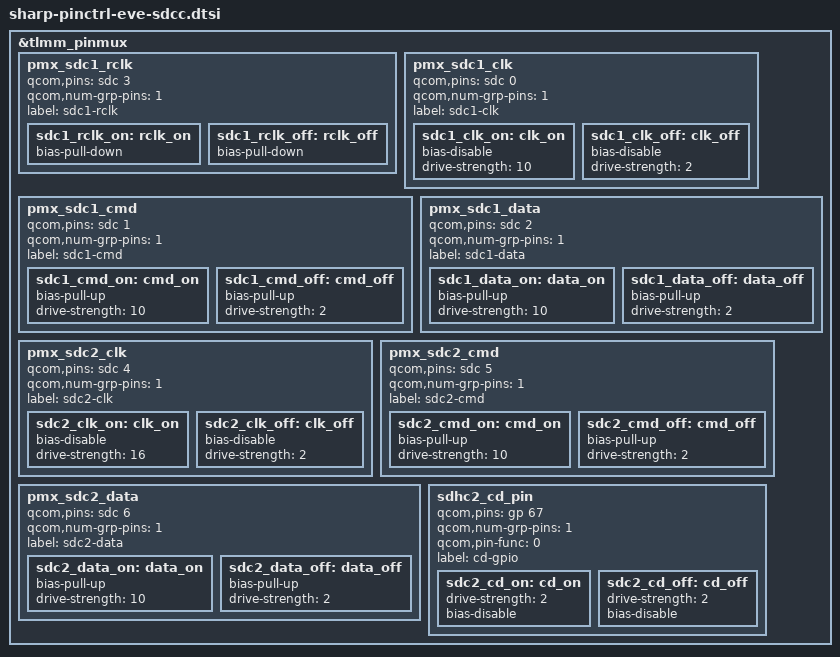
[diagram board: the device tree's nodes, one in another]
/* Copyright (c) 2015, The Linux Foundation. All rights reserved.
 *
 * This program is free software; you can redistribute it and/or modify
 * it under the terms of the GNU General Public License version 2 and
 * only version 2 as published by the Free Software Foundation.
 *
 * This program is distributed in the hope that it will be useful,
 * but WITHOUT ANY WARRANTY; without even the implied warranty of
 * MERCHANTABILITY or FITNESS FOR A PARTICULAR PURPOSE.  See the
 * GNU General Public License for more details.
 */

&tlmm_pinmux {
		pmx_sdc1_rclk {
			qcom,pins = <&sdc 3>;
			qcom,num-grp-pins = <1>;
			label = "sdc1-rclk";
			sdc1_rclk_on: rclk_on {
				bias-pull-down; /* pull down */
			};

			sdc1_rclk_off: rclk_off {
				bias-pull-down; /* pull down */
			};
		};

		pmx_sdc1_clk {
			qcom,pins = <&sdc 0>;
			qcom,num-grp-pins = <1>;
			label = "sdc1-clk";
			sdc1_clk_on: clk_on {
				bias-disable; /* NO pull */
				drive-strength = <10>; /* 10 MA */
			};
			sdc1_clk_off: clk_off {
				bias-disable; /* NO pull */
				drive-strength = <2>; /* 2 MA */
			};
		};

		pmx_sdc1_cmd {
			qcom,pins = <&sdc 1>;
			qcom,num-grp-pins = <1>;
			label = "sdc1-cmd";
			sdc1_cmd_on: cmd_on {
				bias-pull-up; /* pull up */
				drive-strength = <10>; /* 10 MA */
			};
			sdc1_cmd_off: cmd_off {
				bias-pull-up; /* pull up */
				drive-strength = <2>; /* 2 MA */
			};
		};

		pmx_sdc1_data {
			qcom,pins = <&sdc 2>;
			qcom,num-grp-pins = <1>;
			label = "sdc1-data";
			sdc1_data_on: data_on {
				bias-pull-up; /* pull up */
				drive-strength = <10>; /* 10 MA */
			};
			sdc1_data_off: data_off {
				bias-pull-up; /* pull up */
				drive-strength = <2>; /* 2 MA */
			};
		};

		pmx_sdc2_clk {
			qcom,pins = <&sdc 4>;
			qcom,num-grp-pins = <1>;
			label = "sdc2-clk";
			sdc2_clk_on: clk_on {
				bias-disable; /* NO pull */
				drive-strength = <16>; /* 16 MA */
			};
			sdc2_clk_off: clk_off {
				bias-disable; /* NO pull */
				drive-strength = <2>; /* 2 MA */
			};
		};

		pmx_sdc2_cmd {
			qcom,pins = <&sdc 5>;
			qcom,num-grp-pins = <1>;
			label = "sdc2-cmd";
			sdc2_cmd_on: cmd_on {
				bias-pull-up; /* pull up */
				drive-strength = <10>; /* 10 MA */
			};
			sdc2_cmd_off: cmd_off {
				bias-pull-up; /* pull up */
				drive-strength = <2>; /* 2 MA */
			};
		};

		pmx_sdc2_data {
			qcom,pins = <&sdc 6>;
			qcom,num-grp-pins = <1>;
			label = "sdc2-data";
			sdc2_data_on: data_on {
				bias-pull-up; /* pull up */
				drive-strength = <10>; /* 10 MA */
			};
			sdc2_data_off: data_off {
				bias-pull-up; /* pull up */
				drive-strength = <2>; /* 2 MA */
			};
		};

		sdhc2_cd_pin {
			qcom,pins = <&gp 67>;
			qcom,num-grp-pins = <1>;
			qcom,pin-func = <0>;
			label = "cd-gpio";
			sdc2_cd_on: cd_on {
				drive-strength = <2>;
				/delete-property/ bias-pull-up;
				bias-disable;
			};
			sdc2_cd_off: cd_off {
				drive-strength = <2>;
				bias-disable;
			};
		};
};
